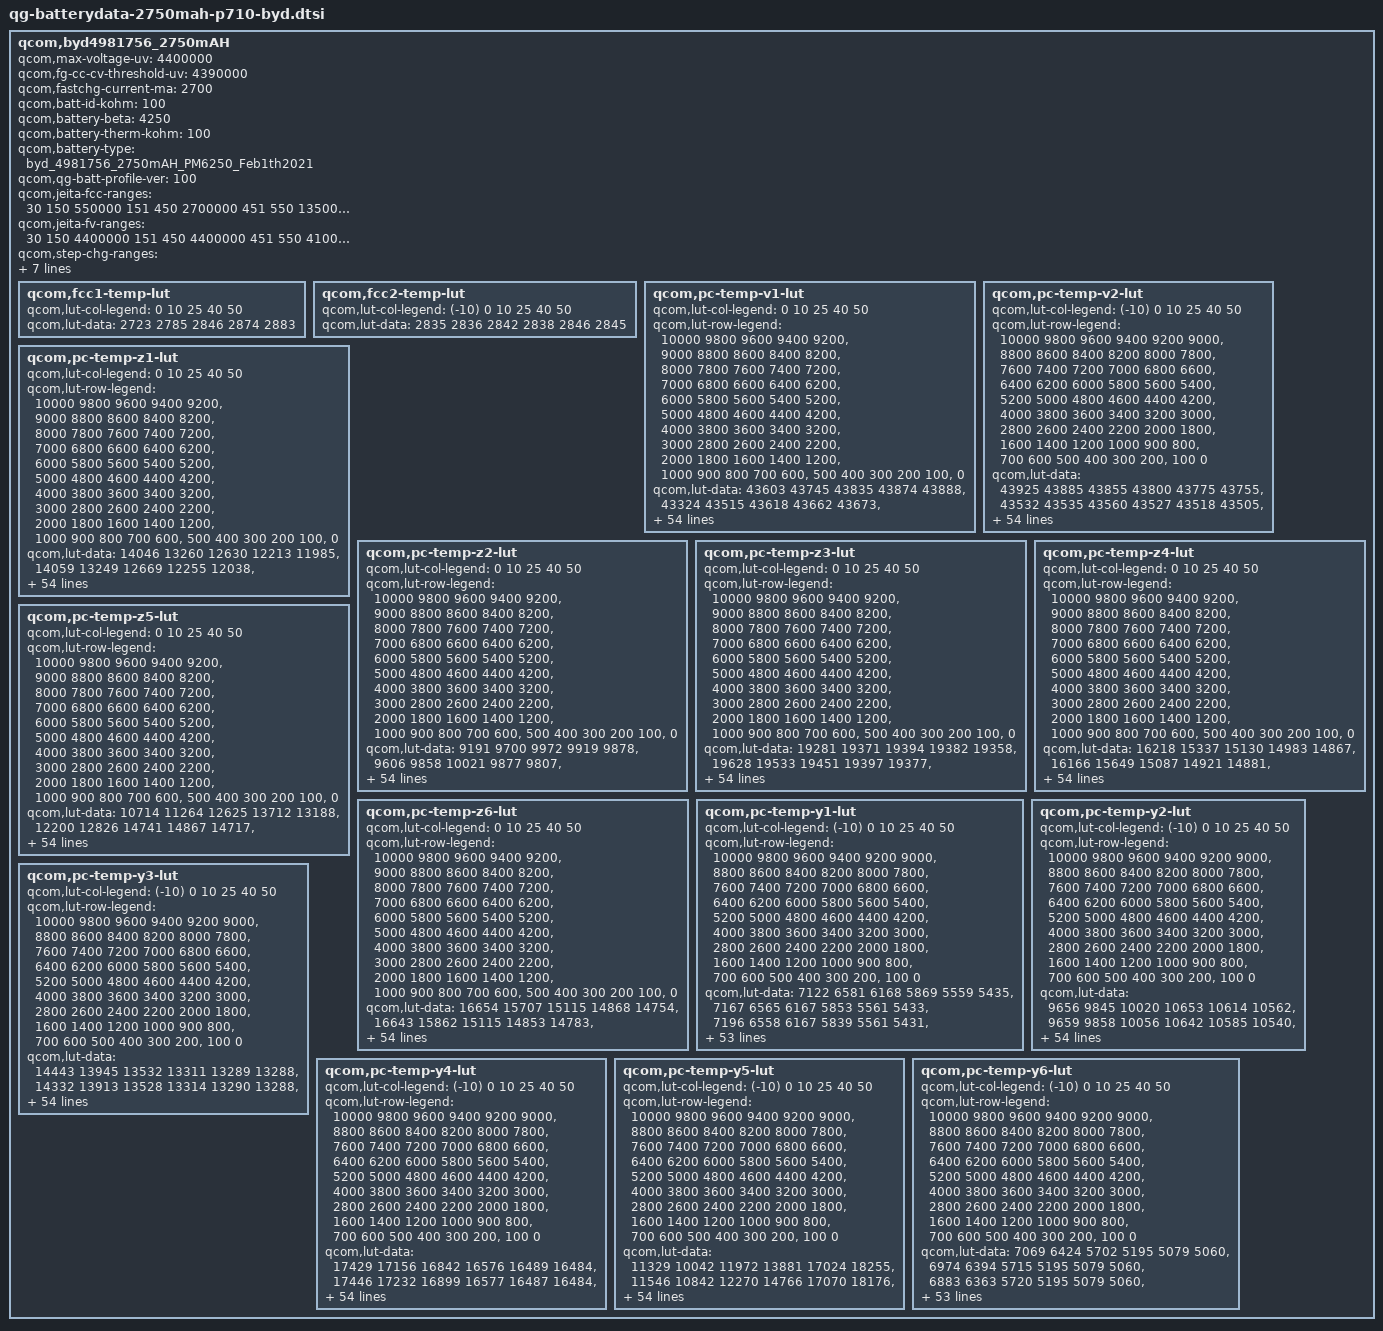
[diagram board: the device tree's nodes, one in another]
/*
 * Copyright (c) 2018-2019, The Linux Foundation. All rights reserved.
 *
 * This program is free software; you can redistribute it and/or modify
 * it under the terms of the GNU General Public License version 2 and
 * only version 2 as published by the Free Software Foundation.
 *
 * This program is distributed in the hope that it will be useful,
 * but WITHOUT ANY WARRANTY; without even the implied warranty of
 * MERCHANTABILITY or FITNESS FOR A PARTICULAR PURPOSE.  See the
 * GNU General Public License for more details.
 */

qcom,byd4981756_2750mAH {
    /* byd4981756_Tinno_P710AE_2750mAH_PM6250_averaged_MasterSlave_Feb1th2021 */
    qcom,max-voltage-uv = <4400000>;
    qcom,fg-cc-cv-threshold-uv = <4390000>;
    qcom,fastchg-current-ma = <2700>;
    qcom,batt-id-kohm = <100>;
    qcom,battery-beta = <4250>;
    qcom,battery-therm-kohm = <100>;
    qcom,battery-type = "byd_4981756_2750mAH_PM6250_Feb1th2021";
    qcom,qg-batt-profile-ver = <100>;

	qcom,jeita-fcc-ranges = <30  150   550000
				151  450  2700000
				451  550  1350000>;
	qcom,jeita-fv-ranges = <30   150   4400000
				151  450  4400000
				451  550  4100000>;
	qcom,step-chg-ranges = <3600000  3800000  5400000
				3800001  4300000  3600000
				4300001  4350000  2500000>;
	qcom,ocv-based-step-chg;

	/* COOL = 15 DegC, WARM = 45 DegC */
	qcom,jeita-soft-thresholds = <0x45E7 0x20C1>;
	
	/* COLD = 3 DegC, HOT = 55 DegC */
	qcom,jeita-hard-thresholds = <0x54E5 0x1815>;
	
	/* COOL hys = 17 DegC, WARM hys = 42 DegC */
	qcom,jeita-soft-hys-thresholds = <0x4341 0x23D3>;
	
	qcom,jeita-soft-fcc-ua = <550000 1350000>;
	qcom,jeita-soft-fv-uv = <4400000 4100000>;

	qcom,fcc1-temp-lut {
		qcom,lut-col-legend = <0 10 25 40 50>;
		qcom,lut-data = <2723 2785 2846 2874 2883>;
	};

	qcom,fcc2-temp-lut {
		qcom,lut-col-legend = <(-10) 0 10 25 40 50>;
		qcom,lut-data = <2835 2836 2842 2838 2846 2845>;
	};

	qcom,pc-temp-v1-lut {
		qcom,lut-col-legend = <0 10 25 40 50>;
		qcom,lut-row-legend = <10000 9800 9600 9400 9200>,
			<9000 8800 8600 8400 8200>,
			<8000 7800 7600 7400 7200>,
			<7000 6800 6600 6400 6200>,
			<6000 5800 5600 5400 5200>,
			<5000 4800 4600 4400 4200>,
			<4000 3800 3600 3400 3200>,
			<3000 2800 2600 2400 2200>,
			<2000 1800 1600 1400 1200>,
			<1000 900 800 700 600>,
			<500 400 300 200 100>,
			<0>;
		qcom,lut-data = <43603 43745 43835 43874 43888>,
			<43324 43515 43618 43662 43673>,
			<43062 43267 43392 43445 43458>,
			<42819 43018 43153 43213 43232>,
			<42590 42777 42910 42978 43001>,
			<42366 42539 42671 42742 42768>,
			<42148 42309 42433 42504 42532>,
			<41935 42085 42198 42268 42294>,
			<41725 41866 41965 42035 42059>,
			<41518 41650 41737 41804 41824>,
			<41335 41441 41510 41574 41594>,
			<41183 41259 41294 41347 41367>,
			<41014 41108 41110 41129 41145>,
			<40744 40930 40953 40930 40930>,
			<40400 40636 40757 40731 40721>,
			<40142 40302 40452 40508 40519>,
			<39962 40084 40160 40280 40323>,
			<39813 39933 40001 40092 40137>,
			<39685 39796 39887 39941 39965>,
			<39575 39673 39744 39783 39790>,
			<39456 39546 39564 39599 39602>,
			<39328 39352 39367 39400 39406>,
			<39189 39072 39145 39193 39203>,
			<39016 38859 38926 38978 38992>,
			<38816 38738 38782 38809 38819>,
			<38661 38645 38681 38685 38692>,
			<38551 38563 38588 38578 38582>,
			<38464 38494 38493 38477 38479>,
			<38398 38430 38404 38385 38384>,
			<38345 38368 38326 38303 38299>,
			<38302 38312 38256 38231 38224>,
			<38265 38264 38195 38165 38153>,
			<38233 38221 38143 38106 38089>,
			<38207 38183 38097 38049 38028>,
			<38185 38152 38057 37996 37968>,
			<38161 38121 38021 37945 37909>,
			<38134 38089 37981 37893 37848>,
			<38102 38056 37942 37845 37789>,
			<38057 38006 37891 37787 37722>,
			<37991 37914 37812 37706 37634>,
			<37908 37802 37709 37602 37528>,
			<37787 37683 37593 37486 37409>,
			<37644 37548 37455 37349 37273>,
			<37486 37390 37305 37201 37122>,
			<37344 37250 37168 37068 36994>,
			<37250 37169 37077 36990 36930>,
			<37217 37150 37051 36965 36906>,
			<37190 37130 37035 36946 36888>,
			<37164 37117 37017 36928 36868>,
			<37113 37066 36962 36858 36776>,
			<36878 36809 36714 36575 36478>,
			<36439 36379 36282 36129 36032>,
			<35868 35807 35714 35554 35456>,
			<35094 35027 34945 34770 34670>,
			<33875 33819 33765 33558 33448>,
			<30000 30000 30000 30000 30000>;
	};

	qcom,pc-temp-v2-lut {
		qcom,lut-col-legend = <(-10) 0 10 25 40 50>;
		qcom,lut-row-legend = <10000 9800 9600 9400 9200 9000>,
			<8800 8600 8400 8200 8000 7800>,
			<7600 7400 7200 7000 6800 6600>,
			<6400 6200 6000 5800 5600 5400>,
			<5200 5000 4800 4600 4400 4200>,
			<4000 3800 3600 3400 3200 3000>,
			<2800 2600 2400 2200 2000 1800>,
			<1600 1400 1200 1000 900 800>,
			<700 600 500 400 300 200>,
			<100 0>;
		qcom,lut-data = <43925 43885 43855 43800 43775 43755>,
			<43532 43535 43560 43527 43518 43505>,
			<43175 43215 43281 43264 43266 43259>,
			<42854 42928 43017 43011 43021 43017>,
			<42565 42668 42769 42768 42781 42780>,
			<42301 42421 42523 42528 42542 42543>,
			<42061 42187 42273 42288 42305 42306>,
			<41837 41957 42031 42052 42069 42070>,
			<41606 41701 41813 41822 41837 41838>,
			<41380 41433 41608 41597 41607 41608>,
			<41225 41232 41395 41374 41380 41382>,
			<41142 41098 41165 41148 41156 41159>,
			<41046 40967 40948 40935 40939 40941>,
			<40821 40806 40777 40759 40739 40730>,
			<40475 40616 40618 40594 40545 40524>,
			<40121 40344 40389 40377 40343 40327>,
			<39721 39918 40054 40084 40133 40138>,
			<39415 39565 39765 39844 39938 39956>,
			<39256 39374 39582 39709 39773 39786>,
			<39127 39223 39422 39591 39609 39614>,
			<38944 39076 39234 39405 39404 39409>,
			<38716 38939 39028 39149 39164 39174>,
			<38545 38782 38847 38930 38956 38968>,
			<38437 38561 38691 38759 38780 38790>,
			<38351 38360 38549 38612 38627 38634>,
			<38274 38256 38416 38487 38501 38506>,
			<38206 38185 38292 38379 38393 38395>,
			<38142 38124 38183 38280 38293 38293>,
			<38084 38069 38083 38189 38202 38200>,
			<38028 38021 38004 38107 38119 38115>,
			<37973 37976 37953 38031 38046 38042>,
			<37919 37933 37913 37961 37978 37973>,
			<37866 37891 37873 37897 37913 37906>,
			<37815 37851 37834 37838 37849 37842>,
			<37763 37809 37794 37783 37780 37768>,
			<37707 37764 37754 37734 37698 37672>,
			<37648 37716 37710 37685 37612 37571>,
			<37585 37661 37658 37621 37529 37477>,
			<37517 37596 37594 37544 37445 37388>,
			<37444 37523 37518 37463 37364 37302>,
			<37362 37435 37421 37380 37287 37224>,
			<37278 37334 37314 37281 37195 37133>,
			<37194 37216 37194 37161 37079 37021>,
			<37119 37089 37052 37026 36944 36883>,
			<37041 36978 36928 36910 36843 36789>,
			<36961 36911 36867 36868 36817 36764>,
			<36922 36884 36848 36857 36806 36752>,
			<36875 36855 36825 36836 36788 36734>,
			<36805 36808 36788 36807 36751 36694>,
			<36681 36705 36687 36721 36621 36541>,
			<36421 36454 36392 36431 36255 36149>,
			<35971 35982 35897 35949 35741 35630>,
			<35323 35336 35247 35340 35082 34961>,
			<34382 34430 34360 34540 34223 34107>,
			<32926 33127 33126 33329 33003 32849>,
			<28320 28259 28033 29010 27982 27904>;
	};

	qcom,pc-temp-z1-lut {
		qcom,lut-col-legend = <0 10 25 40 50>;
		qcom,lut-row-legend = <10000 9800 9600 9400 9200>,
			<9000 8800 8600 8400 8200>,
			<8000 7800 7600 7400 7200>,
			<7000 6800 6600 6400 6200>,
			<6000 5800 5600 5400 5200>,
			<5000 4800 4600 4400 4200>,
			<4000 3800 3600 3400 3200>,
			<3000 2800 2600 2400 2200>,
			<2000 1800 1600 1400 1200>,
			<1000 900 800 700 600>,
			<500 400 300 200 100>,
			<0>;
		qcom,lut-data = <14046 13260 12630 12213 11985>,
			<14059 13249 12669 12255 12038>,
			<14072 13281 12678 12245 12033>,
			<14088 13306 12664 12227 12026>,
			<14108 13289 12649 12215 12016>,
			<14118 13253 12630 12203 12008>,
			<14120 13245 12608 12188 12001>,
			<14118 13249 12598 12177 11996>,
			<14094 13254 12597 12174 11992>,
			<14051 13237 12598 12171 11989>,
			<14016 13209 12594 12168 11986>,
			<13987 13204 12587 12164 11984>,
			<13959 13218 12586 12161 11982>,
			<13923 13228 12589 12160 11980>,
			<13886 13205 12590 12158 11979>,
			<13878 13167 12573 12153 11979>,
			<13900 13161 12556 12145 11978>,
			<13919 13172 12556 12144 11978>,
			<13912 13179 12560 12148 11979>,
			<13898 13191 12566 12151 11980>,
			<13896 13208 12577 12152 11981>,
			<13936 13213 12588 12154 11981>,
			<13980 13217 12595 12157 11982>,
			<13985 13219 12601 12163 11985>,
			<13976 13219 12608 12168 11989>,
			<13976 13219 12615 12172 11993>,
			<13992 13228 12621 12176 11998>,
			<14007 13248 12629 12181 12002>,
			<14003 13258 12636 12186 12007>,
			<13986 13257 12637 12191 12011>,
			<13981 13256 12638 12195 12015>,
			<14001 13260 12642 12200 12019>,
			<14025 13269 12660 12207 12024>,
			<14029 13277 12675 12214 12029>,
			<14029 13298 12674 12221 12035>,
			<14033 13315 12672 12229 12041>,
			<14065 13310 12675 12236 12047>,
			<14101 13298 12690 12243 12052>,
			<14105 13296 12701 12250 12057>,
			<14103 13319 12704 12256 12063>,
			<14100 13339 12707 12263 12070>,
			<14115 13336 12714 12269 12075>,
			<14131 13332 12724 12274 12080>,
			<14162 13359 12725 12284 12085>,
			<14160 13373 12732 12291 12088>,
			<14126 13363 12753 12292 12088>,
			<14157 13378 12746 12293 12088>,
			<14167 13356 12730 12292 12090>,
			<14166 13359 12753 12301 12095>,
			<14194 13344 12732 12311 12104>,
			<14202 13396 12754 12322 12115>,
			<14233 13398 12777 12334 12127>,
			<14244 13439 12799 12349 12143>,
			<14283 13468 12835 12373 12164>,
			<14283 13468 12835 12373 12164>,
			<14283 13468 12835 12373 12164>;
	};

	qcom,pc-temp-z2-lut {
		qcom,lut-col-legend = <0 10 25 40 50>;
		qcom,lut-row-legend = <10000 9800 9600 9400 9200>,
			<9000 8800 8600 8400 8200>,
			<8000 7800 7600 7400 7200>,
			<7000 6800 6600 6400 6200>,
			<6000 5800 5600 5400 5200>,
			<5000 4800 4600 4400 4200>,
			<4000 3800 3600 3400 3200>,
			<3000 2800 2600 2400 2200>,
			<2000 1800 1600 1400 1200>,
			<1000 900 800 700 600>,
			<500 400 300 200 100>,
			<0>;
		qcom,lut-data = <9191 9700 9972 9919 9878>,
			<9606 9858 10021 9877 9807>,
			<9811 9917 10051 9860 9798>,
			<9806 9944 10028 9873 9766>,
			<9788 9935 9995 9877 9747>,
			<9775 9911 9966 9873 9732>,
			<9765 9889 9939 9836 9717>,
			<9756 9864 9932 9797 9708>,
			<9749 9849 9931 9773 9714>,
			<9742 9849 9932 9756 9725>,
			<9742 9850 9935 9757 9730>,
			<9778 9855 9939 9767 9731>,
			<9816 9871 9936 9772 9732>,
			<9803 9890 9924 9774 9737>,
			<9762 9910 9920 9775 9744>,
			<9746 9929 9944 9782 9749>,
			<9756 9936 9967 9795 9753>,
			<9770 9939 9954 9801 9758>,
			<9781 9943 9923 9803 9766>,
			<9794 9953 9920 9806 9777>,
			<9808 9964 9967 9820 9798>,
			<9826 9966 10005 9838 9821>,
			<9842 9966 10006 9842 9823>,
			<9848 9966 10001 9843 9820>,
			<9851 9966 10002 9851 9819>,
			<9854 9966 10005 9910 9829>,
			<9860 9965 10006 9959 9836>,
			<9868 9961 10009 9928 9794>,
			<9873 9959 10013 9862 9712>,
			<9880 9958 10007 9815 9690>,
			<9883 9958 9991 9775 9690>,
			<9885 9961 9986 9758 9693>,
			<9887 9969 9987 9767 9708>,
			<9891 9980 9990 9784 9732>,
			<9900 9995 10003 9803 9756>,
			<9910 10011 10026 9828 9782>,
			<9924 10022 10045 9856 9809>,
			<9937 10032 10062 9891 9838>,
			<9908 10045 10078 9919 9863>,
			<9794 10066 10098 9935 9882>,
			<9734 10081 10115 9946 9899>,
			<9804 10080 10118 9948 9901>,
			<9902 10079 10118 9945 9900>,
			<10074 10083 10115 9944 9895>,
			<10927 10117 10110 9950 9884>,
			<12619 10152 10125 9966 9872>,
			<12670 13981 10117 9964 9876>,
			<12559 11497 10080 9968 9890>,
			<12511 12956 10086 10002 9937>,
			<12243 11888 10126 10043 9935>,
			<12092 12892 10124 9953 9827>,
			<11672 10240 10071 9875 9765>,
			<10970 12667 10026 9857 9735>,
			<10339 12966 10000 9825 9690>,
			<10339 12966 10000 9825 9690>,
			<10339 12966 10000 9825 9690>;
	};

	qcom,pc-temp-z3-lut {
		qcom,lut-col-legend = <0 10 25 40 50>;
		qcom,lut-row-legend = <10000 9800 9600 9400 9200>,
			<9000 8800 8600 8400 8200>,
			<8000 7800 7600 7400 7200>,
			<7000 6800 6600 6400 6200>,
			<6000 5800 5600 5400 5200>,
			<5000 4800 4600 4400 4200>,
			<4000 3800 3600 3400 3200>,
			<3000 2800 2600 2400 2200>,
			<2000 1800 1600 1400 1200>,
			<1000 900 800 700 600>,
			<500 400 300 200 100>,
			<0>;
		qcom,lut-data = <19281 19371 19394 19382 19358>,
			<19628 19533 19451 19397 19377>,
			<19814 19592 19485 19415 19393>,
			<19839 19628 19501 19444 19427>,
			<19851 19643 19508 19454 19434>,
			<19852 19652 19509 19455 19437>,
			<19844 19653 19510 19453 19437>,
			<19835 19648 19509 19449 19436>,
			<19827 19641 19503 19442 19434>,
			<19818 19633 19496 19434 19431>,
			<19807 19621 19494 19431 19428>,
			<19789 19604 19492 19430 19425>,
			<19777 19576 19483 19427 19422>,
			<19777 19560 19462 19421 19418>,
			<19778 19573 19453 19417 19414>,
			<19770 19592 19466 19418 19410>,
			<19749 19592 19479 19423 19406>,
			<19724 19576 19471 19422 19401>,
			<19695 19559 19449 19408 19394>,
			<19663 19547 19444 19400 19391>,
			<19654 19538 19453 19403 19391>,
			<19658 19542 19460 19406 19393>,
			<19664 19562 19458 19405 19396>,
			<19678 19572 19456 19402 19401>,
			<19702 19570 19455 19403 19410>,
			<19711 19567 19453 19438 19438>,
			<19709 19564 19453 19468 19461>,
			<19707 19561 19471 19467 19460>,
			<19703 19560 19492 19464 19452>,
			<19698 19559 19494 19459 19444>,
			<19692 19559 19493 19446 19433>,
			<19684 19558 19491 19435 19422>,
			<19675 19557 19484 19428 19415>,
			<19666 19556 19475 19422 19408>,
			<19658 19553 19468 19415 19400>,
			<19649 19550 19461 19408 19391>,
			<19641 19544 19455 19402 19385>,
			<19630 19535 19451 19396 19382>,
			<19564 19531 19446 19392 19380>,
			<19370 19528 19441 19391 19381>,
			<19267 19526 19437 19390 19384>,
			<19265 19522 19437 19392 19388>,
			<19264 19518 19438 19399 19393>,
			<19262 19515 19434 19400 19399>,
			<19259 19502 19423 19397 19402>,
			<19257 19474 19411 19378 19377>,
			<19257 19370 19410 19371 19367>,
			<19257 19360 19402 19369 19358>,
			<19257 19265 19399 19356 19344>,
			<19257 19259 19388 19352 19357>,
			<19257 19348 19390 19383 19387>,
			<19258 19267 19399 19394 19390>,
			<19258 19260 19406 19396 19391>,
			<19260 19261 19406 19398 19395>,
			<19260 19261 19406 19398 19395>,
			<19260 19261 19406 19398 19395>;
	};

	qcom,pc-temp-z4-lut {
		qcom,lut-col-legend = <0 10 25 40 50>;
		qcom,lut-row-legend = <10000 9800 9600 9400 9200>,
			<9000 8800 8600 8400 8200>,
			<8000 7800 7600 7400 7200>,
			<7000 6800 6600 6400 6200>,
			<6000 5800 5600 5400 5200>,
			<5000 4800 4600 4400 4200>,
			<4000 3800 3600 3400 3200>,
			<3000 2800 2600 2400 2200>,
			<2000 1800 1600 1400 1200>,
			<1000 900 800 700 600>,
			<500 400 300 200 100>,
			<0>;
		qcom,lut-data = <16218 15337 15130 14983 14867>,
			<16166 15649 15087 14921 14881>,
			<16065 15515 15179 14936 14860>,
			<15881 15343 15095 14959 14929>,
			<15627 15213 14992 14903 14892>,
			<15445 15094 14930 14858 14855>,
			<15312 15007 14879 14819 14820>,
			<15205 14941 14841 14795 14794>,
			<15123 14891 14811 14786 14785>,
			<15055 14851 14792 14780 14780>,
			<14989 14821 14783 14773 14773>,
			<14909 14801 14776 14765 14766>,
			<14852 14785 14764 14755 14760>,
			<14848 14778 14746 14741 14753>,
			<14864 14792 14740 14731 14747>,
			<14866 14814 14772 14737 14741>,
			<14852 14813 14805 14749 14736>,
			<14837 14785 14785 14748 14730>,
			<14826 14761 14733 14721 14721>,
			<14815 14748 14720 14705 14716>,
			<14804 14740 14739 14721 14730>,
			<14791 14773 14770 14756 14763>,
			<14781 14909 14845 14808 14803>,
			<14805 14979 14932 14884 14857>,
			<14875 14969 14941 14904 14875>,
			<14909 14949 14914 14848 14827>,
			<14914 14925 14880 14790 14773>,
			<14914 14890 14840 14771 14759>,
			<14904 14860 14802 14759 14752>,
			<14878 14836 14785 14751 14745>,
			<14853 14815 14773 14746 14739>,
			<14835 14798 14768 14740 14732>,
			<14818 14783 14765 14732 14723>,
			<14801 14773 14763 14727 14715>,
			<14786 14765 14763 14728 14715>,
			<14773 14759 14763 14731 14716>,
			<14762 14753 14762 14733 14718>,
			<14754 14748 14761 14733 14720>,
			<14806 14748 14761 14733 14723>,
			<15004 14755 14762 14739 14730>,
			<15110 14762 14765 14748 14739>,
			<15108 14758 14761 14746 14739>,
			<15105 14749 14749 14736 14735>,
			<15097 14746 14745 14737 14738>,
			<15048 14729 14737 14735 14739>,
			<15006 14702 14700 14702 14698>,
			<14998 14796 14688 14694 14691>,
			<14990 14797 14677 14673 14674>,
			<14979 14886 14662 14657 14652>,
			<14974 14886 14668 14659 14648>,
			<14987 14812 14694 14677 14681>,
			<15010 14912 14693 14684 14696>,
			<15023 14925 14691 14689 14702>,
			<15045 14931 14693 14691 14702>,
			<15045 14931 14693 14691 14702>,
			<15045 14931 14693 14691 14702>;
	};

	qcom,pc-temp-z5-lut {
		qcom,lut-col-legend = <0 10 25 40 50>;
		qcom,lut-row-legend = <10000 9800 9600 9400 9200>,
			<9000 8800 8600 8400 8200>,
			<8000 7800 7600 7400 7200>,
			<7000 6800 6600 6400 6200>,
			<6000 5800 5600 5400 5200>,
			<5000 4800 4600 4400 4200>,
			<4000 3800 3600 3400 3200>,
			<3000 2800 2600 2400 2200>,
			<2000 1800 1600 1400 1200>,
			<1000 900 800 700 600>,
			<500 400 300 200 100>,
			<0>;
		qcom,lut-data = <10714 11264 12625 13712 13188>,
			<12200 12826 14741 14867 14717>,
			<13184 13641 14719 15464 15929>,
			<13617 14419 15214 16169 16550>,
			<13899 15217 15901 16771 17032>,
			<14201 15994 16470 17411 17634>,
			<14512 16678 17072 18174 18509>,
			<14864 17344 17752 18548 19284>,
			<15357 17995 18537 18362 19721>,
			<15909 18868 19235 18100 20063>,
			<16350 19741 19897 18237 20484>,
			<16914 19725 20398 18901 21009>,
			<17561 18740 20113 19366 21460>,
			<19215 18102 18873 19575 21871>,
			<21720 20517 18415 19861 22253>,
			<22398 24256 20430 21317 22628>,
			<21659 24683 22458 23837 23267>,
			<20640 23479 21999 24260 23914>,
			<19623 22768 20746 23294 24625>,
			<18447 22980 20962 22727 25080>,
			<18172 23495 25575 23201 25045>,
			<19811 25507 28997 23799 24699>,
			<22665 31288 26415 22307 22995>,
			<27862 34103 21543 17567 18195>,
			<35862 30646 18952 15911 16211>,
			<38605 25840 17236 17440 18158>,
			<36874 23807 16669 19396 20633>,
			<34415 22523 18312 20959 21990>,
			<32628 22144 20987 22284 22987>,
			<30969 22513 23226 22474 23129>,
			<29506 23200 25429 22343 22836>,
			<28116 24210 27050 22286 22660>,
			<26983 25842 28290 23163 23509>,
			<26375 27550 29130 24413 24630>,
			<25961 29688 29600 25074 24719>,
			<25588 31146 29915 25577 24601>,
			<25224 30844 29867 25637 24430>,
			<24675 29977 29158 24809 24096>,
			<22029 29697 28146 23698 23616>,
			<14708 29835 26221 22282 22683>,
			<10903 29946 24350 20847 21596>,
			<10907 28960 24223 20981 21672>,
			<10915 27371 24437 22191 22927>,
			<10929 27001 23218 22026 24048>,
			<10987 27235 21938 21202 24492>,
			<10943 24594 22693 19128 19781>,
			<10928 17888 23524 18240 17675>,
			<10914 17186 22524 19722 17698>,
			<10911 11309 23619 19491 18316>,
			<10932 11015 20748 18117 27118>,
			<10978 14802 17843 20303 22949>,
			<10918 11175 18107 20130 18915>,
			<10860 10955 18415 18850 17035>,
			<10779 10870 17824 17452 15784>,
			<10779 10870 17824 17452 15784>,
			<10779 10870 17824 17452 15784>;
	};

	qcom,pc-temp-z6-lut {
		qcom,lut-col-legend = <0 10 25 40 50>;
		qcom,lut-row-legend = <10000 9800 9600 9400 9200>,
			<9000 8800 8600 8400 8200>,
			<8000 7800 7600 7400 7200>,
			<7000 6800 6600 6400 6200>,
			<6000 5800 5600 5400 5200>,
			<5000 4800 4600 4400 4200>,
			<4000 3800 3600 3400 3200>,
			<3000 2800 2600 2400 2200>,
			<2000 1800 1600 1400 1200>,
			<1000 900 800 700 600>,
			<500 400 300 200 100>,
			<0>;
		qcom,lut-data = <16654 15707 15115 14868 14754>,
			<16643 15862 15115 14853 14783>,
			<16614 15776 15157 14866 14781>,
			<16499 15662 15116 14884 14825>,
			<16299 15572 15063 14864 14813>,
			<16152 15485 15027 14845 14800>,
			<16041 15415 14995 14825 14785>,
			<15948 15357 14970 14810 14772>,
			<15872 15309 14949 14800 14765>,
			<15806 15271 14935 14793 14761>,
			<15742 15239 14929 14787 14756>,
			<15673 15212 14924 14782 14751>,
			<15621 15186 14912 14776 14745>,
			<15597 15174 14890 14765 14740>,
			<15581 15179 14882 14758 14734>,
			<15566 15187 14899 14761 14729>,
			<15548 15185 14915 14767 14725>,
			<15531 15163 14903 14765 14719>,
			<15515 15147 14871 14747 14711>,
			<15501 15141 14863 14736 14707>,
			<15497 15137 14877 14744 14713>,
			<15500 15155 14898 14761 14728>,
			<15505 15226 14933 14785 14748>,
			<15527 15262 14970 14817 14777>,
			<15573 15260 14974 14827 14788>,
			<15595 15254 14963 14822 14783>,
			<15599 15246 14953 14816 14776>,
			<15601 15233 14948 14810 14770>,
			<15598 15221 14944 14804 14764>,
			<15586 15213 14940 14797 14757>,
			<15575 15207 14937 14789 14749>,
			<15567 15202 14933 14782 14741>,
			<15560 15198 14930 14775 14734>,
			<15553 15196 14927 14770 14727>,
			<15546 15194 14924 14768 14722>,
			<15542 15193 14922 14766 14718>,
			<15540 15192 14922 14765 14716>,
			<15538 15190 14922 14762 14716>,
			<15536 15191 14922 14761 14715>,
			<15534 15199 14923 14764 14719>,
			<15533 15207 14926 14769 14725>,
			<15541 15208 14926 14770 14729>,
			<15550 15209 14926 14770 14730>,
			<15559 15213 14925 14772 14735>,
			<15555 15210 14920 14771 14738>,
			<15546 15194 14902 14748 14707>,
			<15544 15185 14898 14740 14699>,
			<15541 15180 14889 14731 14688>,
			<15539 15173 14883 14718 14671>,
			<15546 15178 14885 14718 14676>,
			<15565 15199 14903 14746 14710>,
			<15589 15211 14913 14759 14722>,
			<15617 15228 14923 14766 14729>,
			<15658 15254 14936 14774 14736>,
			<15658 15254 14936 14774 14736>,
			<15658 15254 14936 14774 14736>;
	};

	qcom,pc-temp-y1-lut {
		qcom,lut-col-legend = <(-10) 0 10 25 40 50>;
		qcom,lut-row-legend = <10000 9800 9600 9400 9200 9000>,
			<8800 8600 8400 8200 8000 7800>,
			<7600 7400 7200 7000 6800 6600>,
			<6400 6200 6000 5800 5600 5400>,
			<5200 5000 4800 4600 4400 4200>,
			<4000 3800 3600 3400 3200 3000>,
			<2800 2600 2400 2200 2000 1800>,
			<1600 1400 1200 1000 900 800>,
			<700 600 500 400 300 200>,
			<100 0>;
		qcom,lut-data = <7122 6581 6168 5869 5559 5435>,
			<7167 6565 6167 5853 5561 5433>,
			<7196 6558 6167 5839 5561 5431>,
			<7213 6557 6167 5828 5559 5429>,
			<7219 6558 6169 5820 5557 5426>,
			<7220 6561 6170 5817 5553 5424>,
			<7205 6570 6173 5820 5548 5421>,
			<7189 6578 6175 5823 5543 5418>,
			<7189 6578 6176 5818 5540 5416>,
			<7194 6574 6176 5807 5538 5413>,
			<7197 6570 6174 5802 5536 5411>,
			<7215 6572 6167 5803 5533 5409>,
			<7231 6575 6162 5803 5529 5408>,
			<7226 6576 6162 5796 5524 5406>,
			<7212 6579 6164 5785 5519 5404>,
			<7206 6578 6170 5785 5519 5403>,
			<7196 6571 6190 5800 5522 5403>,
			<7192 6567 6201 5811 5524 5403>,
			<7222 6576 6190 5807 5520 5402>,
			<7260 6588 6175 5802 5516 5401>,
			<7261 6587 6177 5802 5516 5401>,
			<7245 6576 6186 5805 5517 5402>,
			<7235 6571 6192 5808 5519 5403>,
			<7246 6575 6193 5816 5521 5403>,
			<7258 6579 6191 5824 5523 5405>,
			<7238 6580 6195 5825 5526 5407>,
			<7200 6579 6204 5823 5529 5409>,
			<7190 6577 6207 5824 5532 5412>,
			<7203 6567 6208 5830 5536 5414>,
			<7213 6560 6206 5836 5540 5417>,
			<7208 6574 6196 5841 5545 5420>,
			<7197 6599 6185 5846 5550 5424>,
			<7190 6600 6188 5849 5555 5428>,
			<7181 6581 6208 5851 5559 5431>,
			<7177 6568 6219 5853 5564 5434>,
			<7194 6567 6213 5855 5567 5437>,
			<7213 6567 6206 5859 5571 5440>,
			<7218 6569 6205 5864 5575 5443>,
			<7227 6579 6203 5870 5580 5445>,
			<7233 6585 6201 5876 5583 5448>,
			<7229 6573 6201 5885 5586 5450>,
			<7224 6575 6202 5888 5589 5453>,
			<7224 6612 6219 5902 5596 5458>,
			<7222 6587 6210 5900 5603 5464>,
			<7289 6631 6215 5905 5612 5473>,
			<7316 6640 6225 5916 5622 5475>,
			<7279 6626 6228 5917 5620 5473>,
			<7279 6624 6244 5922 5621 5472>,
			<7299 6638 6254 5915 5614 5472>,
			<7358 6653 6223 5907 5614 5474>,
			<7362 6658 6240 5911 5622 5481>,
			<7306 6685 6269 5932 5637 5491>,
			<7389 6707 6287 5960 5651 5503>,
			<7449 6756 6307 5988 5668 5516>,
			<7449 6756 6307 5988 5668 5516>,
			<7449 6756 6307 5988 5668 5516>;
	};

	qcom,pc-temp-y2-lut {
		qcom,lut-col-legend = <(-10) 0 10 25 40 50>;
		qcom,lut-row-legend = <10000 9800 9600 9400 9200 9000>,
			<8800 8600 8400 8200 8000 7800>,
			<7600 7400 7200 7000 6800 6600>,
			<6400 6200 6000 5800 5600 5400>,
			<5200 5000 4800 4600 4400 4200>,
			<4000 3800 3600 3400 3200 3000>,
			<2800 2600 2400 2200 2000 1800>,
			<1600 1400 1200 1000 900 800>,
			<700 600 500 400 300 200>,
			<100 0>;
		qcom,lut-data = <9656 9845 10020 10653 10614 10562>,
			<9659 9858 10056 10642 10585 10540>,
			<9662 9874 10092 10629 10556 10513>,
			<9664 9894 10124 10615 10529 10486>,
			<9666 9917 10152 10599 10505 10461>,
			<9668 9942 10175 10583 10487 10442>,
			<9671 9966 10197 10563 10474 10424>,
			<9673 9998 10210 10545 10463 10410>,
			<9672 10089 10203 10538 10451 10401>,
			<9669 10247 10181 10534 10438 10388>,
			<9668 10292 10196 10527 10429 10383>,
			<9669 10214 10432 10513 10420 10377>,
			<9669 10147 10626 10502 10414 10373>,
			<9669 10223 10575 10518 10413 10369>,
			<9669 10369 10476 10556 10419 10363>,
			<9667 10337 10465 10592 10429 10362>,
			<9664 9951 10525 10626 10457 10364>,
			<9662 9697 10599 10669 10494 10368>,
			<9662 9684 10682 10754 10557 10468>,
			<9662 9677 10765 10835 10615 10589>,
			<9662 9674 10823 10833 10622 10588>,
			<9662 9672 10872 10789 10619 10547>,
			<9661 9672 10883 10769 10617 10533>,
			<9661 9672 10808 10774 10608 10539>,
			<9661 9673 10707 10783 10603 10549>,
			<9660 9672 10648 10798 10615 10560>,
			<9660 9671 10597 10830 10639 10574>,
			<9660 9669 10482 10865 10664 10588>,
			<9660 9667 10173 10908 10695 10605>,
			<9659 9666 9918 10939 10721 10625>,
			<9659 9665 9819 10950 10735 10652>,
			<9659 9664 9755 10958 10748 10678>,
			<9659 9663 9729 10955 10770 10687>,
			<9659 9662 9715 10930 10799 10692>,
			<9659 9661 9704 10905 10809 10693>,
			<9658 9660 9695 10889 10777 10681>,
			<9658 9659 9687 10874 10745 10662>,
			<9658 9659 9681 10850 10742 10646>,
			<9658 9658 9676 10815 10744 10631>,
			<9658 9658 9672 10791 10738 10620>,
			<9657 9657 9668 10774 10708 10612>,
			<9657 9657 9666 10748 10696 10604>,
			<9657 9657 9663 10701 10696 10589>,
			<9656 9656 9662 10629 10672 10602>,
			<9656 9656 9663 10621 10647 10541>,
			<9656 9656 9660 10571 10568 10442>,
			<9656 9656 9659 10614 10567 10425>,
			<9656 9655 9658 10603 10614 10440>,
			<9655 9655 9657 10616 10630 10454>,
			<9655 9655 9657 10634 10630 10443>,
			<9655 9655 9656 10572 10578 10421>,
			<9655 9654 9655 10499 10517 10378>,
			<9654 9654 9654 10477 10483 10308>,
			<9652 9654 9653 10505 10427 10212>,
			<9652 9654 9653 10505 10427 10212>,
			<9652 9654 9653 10505 10427 10212>;
	};

	qcom,pc-temp-y3-lut {
		qcom,lut-col-legend = <(-10) 0 10 25 40 50>;
		qcom,lut-row-legend = <10000 9800 9600 9400 9200 9000>,
			<8800 8600 8400 8200 8000 7800>,
			<7600 7400 7200 7000 6800 6600>,
			<6400 6200 6000 5800 5600 5400>,
			<5200 5000 4800 4600 4400 4200>,
			<4000 3800 3600 3400 3200 3000>,
			<2800 2600 2400 2200 2000 1800>,
			<1600 1400 1200 1000 900 800>,
			<700 600 500 400 300 200>,
			<100 0>;
		qcom,lut-data = <14443 13945 13532 13311 13289 13288>,
			<14332 13913 13528 13314 13290 13288>,
			<14226 13882 13523 13316 13291 13288>,
			<14128 13853 13518 13319 13293 13289>,
			<14042 13824 13513 13320 13294 13289>,
			<13970 13797 13508 13321 13295 13290>,
			<13915 13771 13500 13321 13296 13291>,
			<13863 13746 13495 13321 13296 13293>,
			<13794 13721 13502 13322 13297 13294>,
			<13715 13691 13522 13324 13299 13295>,
			<13678 13648 13525 13326 13299 13296>,
			<13664 13543 13489 13328 13300 13297>,
			<13658 13465 13452 13330 13300 13297>,
			<13670 13479 13437 13334 13303 13298>,
			<13692 13506 13426 13339 13308 13298>,
			<13686 13508 13419 13338 13309 13300>,
			<13622 13479 13415 13326 13307 13302>,
			<13581 13453 13410 13319 13306 13304>,
			<13606 13440 13402 13321 13306 13305>,
			<13641 13432 13391 13323 13306 13305>,
			<13640 13430 13379 13322 13304 13303>,
			<13621 13429 13364 13314 13299 13296>,
			<13612 13427 13350 13309 13294 13291>,
			<13616 13405 13334 13305 13291 13289>,
			<13625 13382 13323 13303 13290 13288>,
			<13639 13383 13325 13302 13289 13288>,
			<13661 13392 13328 13302 13289 13288>,
			<13685 13403 13324 13301 13288 13287>,
			<13708 13422 13289 13300 13287 13286>,
			<13733 13446 13264 13299 13286 13285>,
			<13760 13469 13269 13299 13287 13285>,
			<13788 13494 13278 13298 13287 13285>,
			<13816 13522 13287 13298 13288 13286>,
			<13844 13552 13297 13298 13289 13287>,
			<13874 13584 13308 13298 13289 13288>,
			<13906 13617 13322 13299 13289 13287>,
			<13939 13651 13338 13300 13289 13287>,
			<13973 13685 13354 13300 13288 13287>,
			<14008 13718 13371 13300 13287 13288>,
			<14042 13749 13390 13300 13287 13288>,
			<14073 13778 13414 13302 13290 13290>,
			<14104 13807 13446 13304 13291 13291>,
			<14139 13836 13486 13306 13292 13290>,
			<14194 13872 13507 13304 13288 13287>,
			<14192 13848 13489 13303 13287 13286>,
			<14289 13938 13550 13306 13296 13295>,
			<14343 13977 13595 13313 13300 13298>,
			<14398 14024 13646 13315 13303 13300>,
			<14459 14067 13689 13324 13305 13301>,
			<14527 14098 13740 13327 13302 13298>,
			<14603 14129 13791 13323 13299 13296>,
			<14712 14197 13893 13325 13302 13299>,
			<14867 14332 14034 13336 13310 13310>,
			<15363 14486 14165 13352 13321 13320>,
			<15363 14486 14165 13352 13321 13320>,
			<15363 14486 14165 13352 13321 13320>;
	};

	qcom,pc-temp-y4-lut {
		qcom,lut-col-legend = <(-10) 0 10 25 40 50>;
		qcom,lut-row-legend = <10000 9800 9600 9400 9200 9000>,
			<8800 8600 8400 8200 8000 7800>,
			<7600 7400 7200 7000 6800 6600>,
			<6400 6200 6000 5800 5600 5400>,
			<5200 5000 4800 4600 4400 4200>,
			<4000 3800 3600 3400 3200 3000>,
			<2800 2600 2400 2200 2000 1800>,
			<1600 1400 1200 1000 900 800>,
			<700 600 500 400 300 200>,
			<100 0>;
		qcom,lut-data = <17429 17156 16842 16576 16489 16484>,
			<17446 17232 16899 16577 16487 16484>,
			<17457 17278 16957 16577 16485 16484>,
			<17462 17301 17008 16576 16483 16483>,
			<17464 17310 17043 16575 16483 16482>,
			<17464 17310 17053 16573 16482 16482>,
			<17452 17288 17043 16570 16483 16481>,
			<17438 17252 17026 16567 16484 16481>,
			<17463 17211 17006 16567 16485 16481>,
			<17552 17156 16984 16568 16488 16482>,
			<17649 17165 16982 16569 16491 16484>,
			<17776 17465 17044 16568 16496 16486>,
			<17857 17720 17126 16568 16502 16490>,
			<17729 17674 17208 16595 16512 16495>,
			<17436 17541 17285 16645 16524 16501>,
			<17235 17388 17261 16656 16536 16509>,
			<17081 17175 17051 16652 16548 16517>,
			<16986 17047 16928 16650 16564 16529>,
			<16950 17027 16932 16692 16599 16560>,
			<16922 17013 16937 16747 16630 16590>,
			<16861 16982 16915 16729 16618 16585>,
			<16761 16925 16834 16634 16569 16556>,
			<16719 16854 16776 16569 16529 16527>,
			<16718 16737 16751 16538 16498 16498>,
			<16719 16646 16725 16520 16480 16479>,
			<16718 16643 16671 16518 16480 16478>,
			<16717 16651 16603 16517 16482 16477>,
			<16718 16653 16590 16518 16485 16478>,
			<16722 16652 16616 16524 16494 16486>,
			<16728 16653 16635 16528 16504 16496>,
			<16737 16659 16632 16528 16517 16508>,
			<16747 16668 16626 16529 16529 16521>,
			<16757 16678 16629 16528 16535 16532>,
			<16766 16691 16642 16525 16538 16543>,
			<16774 16704 16656 16523 16539 16546>,
			<16784 16718 16670 16526 16524 16530>,
			<16791 16732 16684 16529 16505 16510>,
			<16791 16740 16695 16528 16497 16500>,
			<16786 16746 16705 16523 16491 16493>,
			<16779 16748 16707 16521 16491 16493>,
			<16765 16746 16702 16529 16504 16508>,
			<16760 16738 16694 16536 16507 16514>,
			<16767 16708 16685 16541 16505 16513>,
			<16776 16683 16676 16536 16478 16471>,
			<16753 16655 16643 16509 16462 16454>,
			<16782 16671 16666 16531 16485 16497>,
			<16806 16692 16682 16546 16518 16544>,
			<16842 16723 16706 16568 16562 16593>,
			<16884 16765 16747 16609 16604 16625>,
			<16907 16810 16784 16638 16594 16592>,
			<16890 16810 16769 16599 16514 16506>,
			<16860 16774 16758 16593 16511 16505>,
			<16866 16785 16767 16632 16533 16516>,
			<17026 16841 16823 16711 16633 16626>,
			<17026 16841 16823 16711 16633 16626>,
			<17026 16841 16823 16711 16633 16626>;
	};

	qcom,pc-temp-y5-lut {
		qcom,lut-col-legend = <(-10) 0 10 25 40 50>;
		qcom,lut-row-legend = <10000 9800 9600 9400 9200 9000>,
			<8800 8600 8400 8200 8000 7800>,
			<7600 7400 7200 7000 6800 6600>,
			<6400 6200 6000 5800 5600 5400>,
			<5200 5000 4800 4600 4400 4200>,
			<4000 3800 3600 3400 3200 3000>,
			<2800 2600 2400 2200 2000 1800>,
			<1600 1400 1200 1000 900 800>,
			<700 600 500 400 300 200>,
			<100 0>;
		qcom,lut-data = <11329 10042 11972 13881 17024 18255>,
			<11546 10842 12270 14766 17070 18176>,
			<11756 11629 12629 15327 17072 18081>,
			<11949 12356 12984 15636 17037 17978>,
			<12117 12976 13272 15767 16972 17869>,
			<12252 13443 13428 15783 16877 17761>,
			<12378 13811 13480 15529 16567 17659>,
			<12460 14080 13535 15194 16161 17536>,
			<12245 14021 14101 15043 15864 17352>,
			<11644 13524 15390 14941 15583 17080>,
			<11517 13258 15623 14876 15218 16717>,
			<12734 12577 13571 14782 14592 16143>,
			<14616 12094 11878 14652 14188 15520>,
			<17344 14071 12658 14387 14330 14868>,
			<20413 17658 14284 13968 14587 14291>,
			<20272 17925 15074 13566 14468 14191>,
			<15670 14732 15433 13103 13607 14200>,
			<12755 12713 15805 12886 13123 14216>,
			<14830 13144 16382 13715 13346 14164>,
			<17732 14092 16920 15234 13846 14133>,
			<17361 15603 17163 16658 15106 14842>,
			<14418 18091 17314 18192 17558 16910>,
			<12638 18999 17434 18726 18418 18082>,
			<12132 16120 17511 18563 18138 18520>,
			<11873 12867 17618 18356 17757 18730>,
			<11887 12214 19392 18259 17336 18361>,
			<12018 11902 22973 18193 16713 17404>,
			<12130 11857 23010 18139 16038 16445>,
			<12272 11970 16405 18061 15191 15206>,
			<12405 12092 11762 18035 14762 14496>,
			<12476 12189 12003 18593 14892 14439>,
			<12536 12313 12412 19528 15202 14411>,
			<12664 12485 12541 19686 15763 14669>,
			<12936 12739 12587 19381 16880 15795>,
			<13138 12982 12654 19175 17891 16922>,
			<13206 13183 12893 19274 18818 18065>,
			<13260 13361 13154 19407 19418 18885>,
			<13374 13519 13264 18908 18816 18808>,
			<13549 13668 13336 17429 17276 18457>,
			<13602 13695 13330 16679 16862 18351>,
			<13358 13437 13120 16423 17352 18142>,
			<12973 13338 13075 16323 18030 18454>,
			<12457 13431 13228 16306 18837 19696>,
			<12351 13105 12878 15335 17482 18709>,
			<12501 12710 13405 16654 16090 16227>,
			<12589 12918 13039 15361 16302 15294>,
			<12726 12810 13261 15815 15883 14148>,
			<12741 12875 13199 15242 15129 13601>,
			<12821 13172 13137 15613 14695 13446>,
			<13103 13529 13067 15842 14543 13533>,
			<13118 13593 13126 16212 16059 14582>,
			<12766 13268 13205 16345 16726 14872>,
			<12560 13033 13616 17056 18329 18036>,
			<12028 13310 14789 18884 21400 21798>,
			<12028 13310 14789 18884 21400 21798>,
			<12028 13310 14789 18884 21400 21798>;
	};

	qcom,pc-temp-y6-lut {
		qcom,lut-col-legend = <(-10) 0 10 25 40 50>;
		qcom,lut-row-legend = <10000 9800 9600 9400 9200 9000>,
			<8800 8600 8400 8200 8000 7800>,
			<7600 7400 7200 7000 6800 6600>,
			<6400 6200 6000 5800 5600 5400>,
			<5200 5000 4800 4600 4400 4200>,
			<4000 3800 3600 3400 3200 3000>,
			<2800 2600 2400 2200 2000 1800>,
			<1600 1400 1200 1000 900 800>,
			<700 600 500 400 300 200>,
			<100 0>;
		qcom,lut-data = <7069 6424 5702 5195 5079 5060>,
			<6974 6394 5715 5195 5079 5060>,
			<6883 6363 5720 5195 5079 5060>,
			<6799 6331 5718 5194 5079 5061>,
			<6723 6298 5712 5192 5079 5061>,
			<6656 6264 5704 5189 5079 5061>,
			<6598 6229 5688 5186 5080 5062>,
			<6548 6193 5672 5182 5080 5062>,
			<6504 6150 5666 5181 5081 5063>,
			<6465 6104 5663 5180 5082 5064>,
			<6456 6089 5657 5180 5083 5065>,
			<6477 6094 5646 5179 5084 5066>,
			<6494 6099 5638 5179 5086 5068>,
			<6468 6096 5646 5188 5090 5069>,
			<6403 6086 5659 5203 5097 5071>,
			<6340 6058 5652 5205 5101 5074>,
			<6265 5963 5596 5198 5104 5078>,
			<6228 5904 5559 5193 5107 5083>,
			<6240 5902 5554 5206 5116 5092>,
			<6257 5901 5551 5223 5124 5100>,
			<6249 5898 5537 5216 5119 5097>,
			<6212 5891 5507 5183 5101 5083>,
			<6195 5881 5485 5161 5086 5071>,
			<6200 5847 5474 5151 5075 5061>,
			<6209 5817 5465 5145 5069 5055>,
			<6221 5822 5458 5145 5069 5055>,
			<6238 5843 5452 5146 5070 5055>,
			<6256 5865 5452 5147 5070 5055>,
			<6275 5886 5454 5149 5072 5057>,
			<6296 5909 5458 5151 5075 5059>,
			<6319 5935 5475 5153 5079 5062>,
			<6344 5962 5503 5156 5084 5067>,
			<6371 5992 5530 5157 5087 5071>,
			<6400 6024 5558 5159 5089 5075>,
			<6428 6058 5589 5161 5090 5076>,
			<6456 6092 5624 5165 5086 5072>,
			<6484 6127 5663 5170 5081 5066>,
			<6511 6161 5703 5173 5079 5064>,
			<6539 6194 5745 5175 5077 5063>,
			<6565 6224 5787 5179 5078 5063>,
			<6587 6251 5829 5187 5084 5069>,
			<6613 6274 5874 5197 5086 5071>,
			<6646 6296 5922 5207 5087 5071>,
			<6701 6321 5952 5211 5078 5058>,
			<6711 6306 5916 5203 5074 5054>,
			<6801 6383 5993 5223 5089 5073>,
			<6851 6423 6045 5238 5101 5089>,
			<6909 6471 6102 5250 5116 5104>,
			<6973 6520 6158 5272 5128 5114>,
			<7038 6564 6216 5281 5124 5103>,
			<7097 6590 6265 5270 5100 5077>,
			<7182 6641 6356 5283 5103 5081>,
			<7324 6757 6485 5327 5117 5093>,
			<7826 6904 6617 5381 5158 5135>,
			<7826 6904 6617 5381 5158 5135>,
			<7826 6904 6617 5381 5158 5135>;
	};

};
